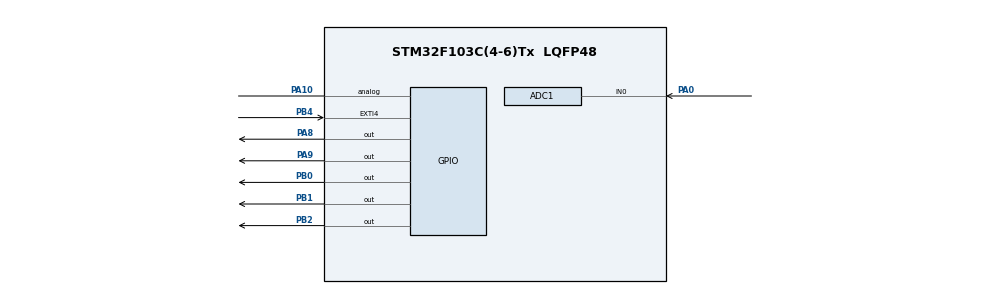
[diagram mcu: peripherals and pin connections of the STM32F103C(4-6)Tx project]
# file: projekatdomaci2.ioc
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ADC1.Channel-0\#ChannelRegularConversion=ADC_CHANNEL_0
ADC1.NbrOfConversionFlag=1
ADC1.Rank-0\#ChannelRegularConversion=1
ADC1.SamplingTime-0\#ChannelRegularConversion=ADC_SAMPLETIME_1CYCLE_5
ADC1.master=1
Mcu.Family=STM32F1
Mcu.Name=STM32F103C(4-6)Tx
Mcu.Package=LQFP48
NVIC.EXTI4_IRQn=true\:0\:0\:false\:false\:true\:true\:true\:true
NVIC.PriorityGroup=NVIC_PRIORITYGROUP_4
PA0-WKUP.Signal=ADCx_IN0
PA10.Signal=GPIO_Analog
PA8.Signal=GPIO_Output
PA9.Signal=GPIO_Output
PB0.Signal=GPIO_Output
PB1.Signal=GPIO_Output
PB2.Signal=GPIO_Output
PB4.Signal=GPXTI4
PC14-OSC32_IN.Mode=LSE-External-Oscillator
PC14-OSC32_IN.Signal=RCC_OSC32_IN
PC15-OSC32_OUT.Mode=LSE-External-Oscillator
PC15-OSC32_OUT.Signal=RCC_OSC32_OUT
PD0-OSC_IN.Mode=HSE-External-Oscillator
PD0-OSC_IN.Signal=RCC_OSC_IN
PD1-OSC_OUT.Mode=HSE-External-Oscillator
PD1-OSC_OUT.Signal=RCC_OSC_OUT
ProjectManager.HeapSize=0x200
ProjectManager.StackSize=0x400
ProjectManager.TargetToolchain=STM32CubeIDE
RCC.APB1Freq_Value=8000000
RCC.APB2Freq_Value=8000000
SH.ADCx_IN0.0=ADC1_IN0,IN0
board=custom

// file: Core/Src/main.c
/* USER CODE BEGIN Header */
/**
  ******************************************************************************
  * @file           : main.c
  * @brief          : Main program body
  ******************************************************************************
  * @attention
  *
  * Copyright (c) 2023 STMicroelectronics.
  * All rights reserved.
  *
  * This software is licensed under terms that can be found in the LICENSE file
  * in the root directory of this software component.
  * If no LICENSE file comes with this software, it is provided AS-IS.
  *
  ******************************************************************************
  */
/* USER CODE END Header */
#include "main.h"
#include <stdio.h>
#include "stdlib.h"
#include "stm32f1xx.h"
#include "stm32f1xx_hal.h"

/* USER CODE BEGIN Includes */
#define MAX_ARRAY_LENGTH 14
#define STEP_PIN GPIO_PIN_8
#define DIR_PIN GPIO_PIN_9
#define ENABLE_PIN GPIO_PIN_10
#define STEPS_PER_REV 200
#define MICROSTEPS 15
#define STEPS_PER_MICROSTEP (STEPS_PER_REV*MICROSTEPS)
#define TEMPERATURE 70 //14*5(name and surname 14 letters)
int tubes[MAX_ARRAY_LENGTH] = {2, 2, 3, 0, 3, 0, 0, 1, 2, 1, 2, 1, 0, 3};//
#define STEP_PIN2 GPIO_PIN_0//motor 2
#define DIR_PIN2 GPIO_PIN_1
#define ENABLE_PIN2 GPIO_PIN_2

/* Private includes ----------------------------------------------------------*/
/* USER CODE BEGIN Includes */

/* USER CODE END Includes */

ADC_HandleTypeDef hadc1;

uint8_t arraylength=MAX_ARRAY_LENGTH;
uint8_t flagTaster = 0;
int currentPosition = 0;
void SystemClock_Config(void);
static void MX_GPIO_Init(void);
static void MX_ADC1_Init(void);

void HAL_GPIO_EXTI_Callback(uint16_t GPIO_Pin){
	flagTaster = 1;
}
float calculateTemperature(uint16_t adcValue) {
    float referenceVoltage = 3.3;
    uint16_t adcMaxValue = 4095;

    float voltage = (float)adcValue*referenceVoltage / adcMaxValue ;
    voltage=voltage-0.5;
	float temperature = voltage*100;//using the TMP36 temperature sensor, which has an offset(voltage-0.5)

    return temperature;
}
void rotateTubes() {
    // storing the value of the last tube
    int lastTube = tubes[MAX_ARRAY_LENGTH-1];

    // Moving all tubes forward
    for (int i = 0; i < MAX_ARRAY_LENGTH - 1; i++) {
        tubes[i] = tubes[i + 1];//  1 2 3 4  4 1 2 3
    }

    // Placing the value of the first tube at the last position
    tubes[0] = lastTube;
}

void step_motor(uint16_t steps, uint8_t dir)
{
// Set the DIR pin to the desired direction
	    if(dir > 0)
	    {
	        HAL_GPIO_WritePin(GPIOA, DIR_PIN, GPIO_PIN_SET);
	    }
	    else
	    {
	        HAL_GPIO_WritePin(GPIOA, DIR_PIN, GPIO_PIN_RESET);
	    }
// Generate the desired number of steps
    for (uint16_t i = 0; i < steps; i++)
    {
        // Generate a pulse on the STEP pin
        HAL_GPIO_WritePin(GPIOA, STEP_PIN,GPIO_PIN_SET);
        HAL_Delay(1000);
        HAL_GPIO_WritePin(GPIOA, STEP_PIN,GPIO_PIN_RESET);
        HAL_Delay(1000);

    }
    currentPosition += dir;//current position of motor
}
int findClosestTube(int value,int stepsPerUnit,int *stepsToMove) {
    int minDistance = MAX_ARRAY_LENGTH;  //
    int closestIndex = -1;

    for (int i = 0; i < MAX_ARRAY_LENGTH; i++) {
        int distance = abs(tubes[i] - value);
        if (distance < minDistance) {
            minDistance = distance;
            closestIndex = i;
        }
    }
        *stepsToMove = minDistance * stepsPerUnit;
        int direction = (closestIndex < currentPosition) ? -1 : 1;

            // Moving motor to the closestIndex
      HAL_GPIO_WritePin(GPIOA, ENABLE_PIN, GPIO_PIN_SET);
      step_motor(*stepsToMove, direction);
       return closestIndex;
    }

    // returning the closest Tube

void removeTube(int index) {
    if (index >= 0 && index < MAX_ARRAY_LENGTH) {

    	//if the index is valid, remove tube and store random value
    	tubes[index]=10;
    }
}

int main(void)
{
	 HAL_GPIO_WritePin(GPIOA,ENABLE_PIN,GPIO_PIN_RESET);
	 HAL_GPIO_WritePin(GPIOB,ENABLE_PIN,GPIO_PIN_RESET);

  /* MCU Configuration--------------------------------------------------------*/

  /* Reset of all peripherals, Initializes the Flash interface and the Systick. */
  HAL_Init();

  /* Configure the system clock */
  SystemClock_Config();

  /* Initialize all configured peripherals */
  MX_GPIO_Init();
  MX_ADC1_Init();

  /* Infinite loop */
  while (1)
  {
	  uint16_t AD_RES = 0;
	 	  if (flagTaster == 1) {
	 			  HAL_ADC_Start(&hadc1);
	 		      HAL_ADC_PollForConversion(&hadc1, 100);
	 		      AD_RES = HAL_ADC_GetValue(&hadc1);
	 		      flagTaster = 0;
	 		          }
	      float temperature = calculateTemperature(AD_RES);//calculating temeprature
	 	 if(temperature<70){
	 		  HAL_GPIO_WritePin(GPIOA,ENABLE_PIN,GPIO_PIN_SET);// set ENABLE_PIN motor1
	 		  step_motor(STEPS_PER_REV*MICROSTEPS,1);
	 		  rotateTubes();
	 		  HAL_Delay(1000);
	 		  }
	 	else{
	 		HAL_GPIO_WritePin(GPIOA,ENABLE_PIN,GPIO_PIN_RESET);
	 		int selectedTube = 2;
	 		int stepsToMove;
	        int index = findClosestTube(selectedTube,STEPS_PER_REV*MICROSTEPS, &stepsToMove);
	        HAL_GPIO_WritePin(GPIOB,ENABLE_PIN2,GPIO_PIN_SET); //enable motor2
	        HAL_GPIO_WritePin(GPIOB,DIR_PIN2,GPIO_PIN_SET);
	         for (int i = 0; i < 180; i++) {
	                //Generate a pulse on the STEP pin of motor 2
	                //
	                HAL_GPIO_WritePin(GPIOA, STEP_PIN2, GPIO_PIN_SET);
	                HAL_Delay(1000);
	                HAL_GPIO_WritePin(GPIOA, STEP_PIN2, GPIO_PIN_RESET);
	                HAL_Delay(1000);
	            }
	         removeTube(index);
	         HAL_GPIO_WritePin(GPIOB,ENABLE_PIN2,GPIO_PIN_RESET); //disable motor2
	         HAL_GPIO_WritePin(GPIOB,DIR_PIN2,GPIO_PIN_RESET);

  }
}

void SystemClock_Config(void)
{
  RCC_OscInitTypeDef RCC_OscInitStruct = {0};
  RCC_ClkInitTypeDef RCC_ClkInitStruct = {0};
  RCC_PeriphCLKInitTypeDef PeriphClkInit = {0};

  /** Initializes the RCC Oscillators according to the specified parameters
  * in the RCC_OscInitTypeDef structure.
  */
  RCC_OscInitStruct.OscillatorType = RCC_OSCILLATORTYPE_HSI;
  RCC_OscInitStruct.HSIState = RCC_HSI_ON;
  RCC_OscInitStruct.HSICalibrationValue = RCC_HSICALIBRATION_DEFAULT;
  RCC_OscInitStruct.PLL.PLLState = RCC_PLL_NONE;
  if (HAL_RCC_OscConfig(&RCC_OscInitStruct) != HAL_OK)
  {
    Error_Handler();
  }

  /** Initializes the CPU, AHB and APB buses clocks
  */
  RCC_ClkInitStruct.ClockType = RCC_CLOCKTYPE_HCLK|RCC_CLOCKTYPE_SYSCLK
                              |RCC_CLOCKTYPE_PCLK1|RCC_CLOCKTYPE_PCLK2;
  RCC_ClkInitStruct.SYSCLKSource = RCC_SYSCLKSOURCE_HSI;
  RCC_ClkInitStruct.AHBCLKDivider = RCC_SYSCLK_DIV1;
  RCC_ClkInitStruct.APB1CLKDivider = RCC_HCLK_DIV1;
  RCC_ClkInitStruct.APB2CLKDivider = RCC_HCLK_DIV1;

  if (HAL_RCC_ClockConfig(&RCC_ClkInitStruct, FLASH_LATENCY_0) != HAL_OK)
  {
    Error_Handler();
  }
  PeriphClkInit.PeriphClockSelection = RCC_PERIPHCLK_ADC;
  PeriphClkInit.AdcClockSelection = RCC_ADCPCLK2_DIV2;
  if (HAL_RCCEx_PeriphCLKConfig(&PeriphClkInit) != HAL_OK)
  {
    Error_Handler();
  }
}

static void MX_ADC1_Init(void)
{

  ADC_ChannelConfTypeDef sConfig = {0};

  /** Common config
  */
  hadc1.Instance = ADC1;
  hadc1.Init.ScanConvMode = ADC_SCAN_DISABLE;
  hadc1.Init.ContinuousConvMode = DISABLE;
  hadc1.Init.DiscontinuousConvMode = DISABLE;
  hadc1.Init.ExternalTrigConv = ADC_SOFTWARE_START;
  hadc1.Init.DataAlign = ADC_DATAALIGN_RIGHT;
  hadc1.Init.NbrOfConversion = 1;
  if (HAL_ADC_Init(&hadc1) != HAL_OK)
  {
    Error_Handler();
  }

  /** Configure Regular Channel
  */
  sConfig.Channel = ADC_CHANNEL_0;
  sConfig.Rank = ADC_REGULAR_RANK_1;
  sConfig.SamplingTime = ADC_SAMPLETIME_1CYCLE_5;
  if (HAL_ADC_ConfigChannel(&hadc1, &sConfig) != HAL_OK)
  {
    Error_Handler();
  }

}

static void MX_GPIO_Init(void)
{
  GPIO_InitTypeDef GPIO_InitStruct = {0};

  /* GPIO Ports Clock Enable */
  __HAL_RCC_GPIOC_CLK_ENABLE();
  __HAL_RCC_GPIOD_CLK_ENABLE();
  __HAL_RCC_GPIOA_CLK_ENABLE();
  __HAL_RCC_GPIOB_CLK_ENABLE();

  /*Configure GPIO pin Output Level */
  HAL_GPIO_WritePin(GPIOB, GPIO_PIN_0|GPIO_PIN_1|GPIO_PIN_2, GPIO_PIN_RESET);

  /*Configure GPIO pin Output Level */
  HAL_GPIO_WritePin(GPIOA, GPIO_PIN_8|GPIO_PIN_9, GPIO_PIN_RESET);

  /*Configure GPIO pins : PB0 PB1 PB2 */
  GPIO_InitStruct.Pin = GPIO_PIN_0|GPIO_PIN_1|GPIO_PIN_2;
  GPIO_InitStruct.Mode = GPIO_MODE_OUTPUT_PP;
  GPIO_InitStruct.Pull = GPIO_NOPULL;
  GPIO_InitStruct.Speed = GPIO_SPEED_FREQ_LOW;
  HAL_GPIO_Init(GPIOB, &GPIO_InitStruct);

  /*Configure GPIO pins : PA8 PA9 */
  GPIO_InitStruct.Pin = GPIO_PIN_8|GPIO_PIN_9;
  GPIO_InitStruct.Mode = GPIO_MODE_OUTPUT_PP;
  GPIO_InitStruct.Pull = GPIO_NOPULL;
  GPIO_InitStruct.Speed = GPIO_SPEED_FREQ_LOW;
  HAL_GPIO_Init(GPIOA, &GPIO_InitStruct);

  /*Configure GPIO pin : PA10 */
  GPIO_InitStruct.Pin = GPIO_PIN_10;
  GPIO_InitStruct.Mode = GPIO_MODE_ANALOG;
  HAL_GPIO_Init(GPIOA, &GPIO_InitStruct);

  /*Configure GPIO pin : PB4 */
  GPIO_InitStruct.Pin = GPIO_PIN_4;
  GPIO_InitStruct.Mode = GPIO_MODE_IT_RISING;
  GPIO_InitStruct.Pull = GPIO_NOPULL;
  HAL_GPIO_Init(GPIOB, &GPIO_InitStruct);

  /* EXTI interrupt init*/
  HAL_NVIC_SetPriority(EXTI4_IRQn, 0, 0);
  HAL_NVIC_EnableIRQ(EXTI4_IRQn);

}
